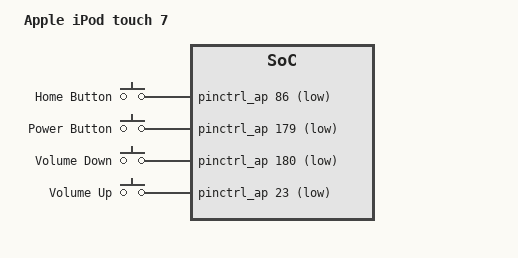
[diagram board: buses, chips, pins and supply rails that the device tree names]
// SPDX-License-Identifier: GPL-2.0+ OR MIT
/*
 * Apple iPod touch 7, N112, iPod9,1 (A2178)
 * Copyright (c) 2022, Konrad Dybcio <konradybcio@kernel.org>
 */

/dts-v1/;

#include "t8010.dtsi"
#include "t8010-common.dtsi"
#include <dt-bindings/input/input.h>

/ {
	compatible = "apple,n112", "apple,t8010", "apple,arm-platform";
	model = "Apple iPod touch 7";
	chassis-type = "handset";

	gpio-keys {
		compatible = "gpio-keys";

		button-home {
			label = "Home Button";
			gpios = <&pinctrl_ap 86 GPIO_ACTIVE_LOW>;
			linux,code = <KEY_HOMEPAGE>;
			wakeup-source;
		};

		button-power {
			label = "Power Button";
			gpios = <&pinctrl_ap 179 GPIO_ACTIVE_LOW>;
			linux,code = <KEY_POWER>;
			wakeup-source;
		};

		button-voldown {
			label = "Volume Down";
			gpios = <&pinctrl_ap 180 GPIO_ACTIVE_LOW>;
			linux,code = <KEY_VOLUMEDOWN>;
		};

		button-volup {
			label = "Volume Up";
			gpios = <&pinctrl_ap 23 GPIO_ACTIVE_LOW>;
			linux,code = <KEY_VOLUMEUP>;
		};
	};
};

&framebuffer0 {
	power-domains = <&ps_disp0_fe &ps_disp0_be &ps_mipi_dsi>;
};
